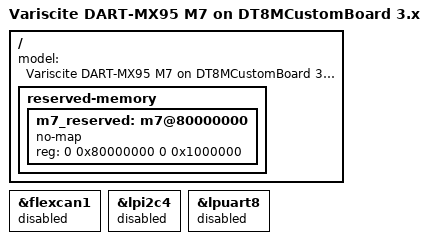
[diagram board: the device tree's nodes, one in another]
// SPDX-License-Identifier: (GPL-2.0+ OR MIT)
/*
 * Copyright 2025 Variscite Ltd.
 */

#include "imx95-var-dart-dt8mcustomboard.dts"

/ {
	model = "Variscite DART-MX95 M7 on DT8MCustomBoard 3.x";

	reserved-memory {
		m7_reserved: m7@80000000 {
			no-map;
			reg = <0 0x80000000 0 0x1000000>;
		};
	};
};

&flexcan1 {
	status = "disabled";
};

&lpi2c4 {
	status = "disabled";
};

&lpuart8 {
	status = "disabled";
};
